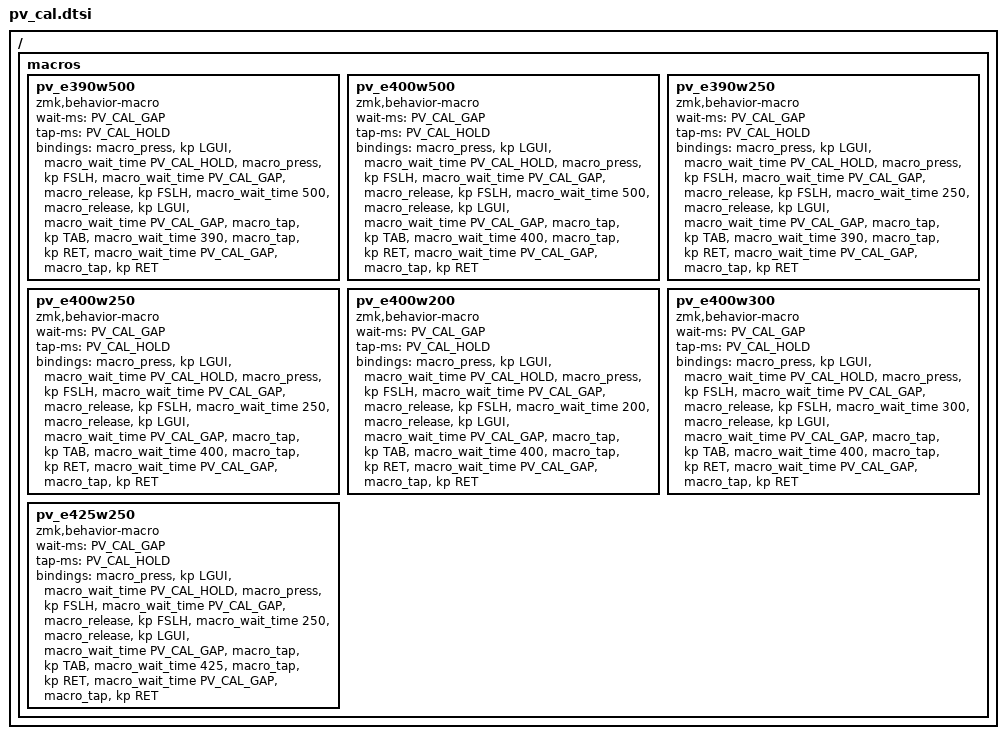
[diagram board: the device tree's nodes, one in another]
/*
 * TEMPORARY Neu paste-values timing calibration — ROUND 4
 *
 * Round 3 CORRECTION: E400@W100 / W150 / E450@W100 were false positives —
 * they did a normal paste + spurious Enter, not paste-as-values.
 * Real hits: E390@W500 ~90%, E400@W250 ~90%. E360 fail, E375 ~30%.
 * Win must be well above 150ms.
 *
 * Combo both lower buttons (pos 6+7) toggles LAYER_PV_CAL. Leave with pos7.
 *
 *               pos0 E390@W500 | pos1 E400@W500
 *               pos2 E390@W250 | pos3 E400@W250
 *               pos4 E400@W200 | pos5 E400@W300
 *               pos6 E425@W250 | pos7 BACK
 *
 * Only count a key as ok if Excel gets *values* (not a normal paste).
 */

#define PV_CAL_HOLD 12
#define PV_CAL_GAP  50

/ {
	macros {
		pv_e390w500: pv_e390w500 {
			compatible = "zmk,behavior-macro";
			#binding-cells = <0>;
			wait-ms = <PV_CAL_GAP>;
			tap-ms = <PV_CAL_HOLD>;
			bindings
				= <&macro_press &kp LGUI>
				, <&macro_wait_time PV_CAL_HOLD>
				, <&macro_press &kp FSLH>
				, <&macro_wait_time PV_CAL_GAP>
				, <&macro_release &kp FSLH>
				, <&macro_wait_time 500>
				, <&macro_release &kp LGUI>
				, <&macro_wait_time PV_CAL_GAP>
				, <&macro_tap &kp TAB>
				, <&macro_wait_time 390>
				, <&macro_tap &kp RET>
				, <&macro_wait_time PV_CAL_GAP>
				, <&macro_tap &kp RET>;
		};
		pv_e400w500: pv_e400w500 {
			compatible = "zmk,behavior-macro";
			#binding-cells = <0>;
			wait-ms = <PV_CAL_GAP>;
			tap-ms = <PV_CAL_HOLD>;
			bindings
				= <&macro_press &kp LGUI>
				, <&macro_wait_time PV_CAL_HOLD>
				, <&macro_press &kp FSLH>
				, <&macro_wait_time PV_CAL_GAP>
				, <&macro_release &kp FSLH>
				, <&macro_wait_time 500>
				, <&macro_release &kp LGUI>
				, <&macro_wait_time PV_CAL_GAP>
				, <&macro_tap &kp TAB>
				, <&macro_wait_time 400>
				, <&macro_tap &kp RET>
				, <&macro_wait_time PV_CAL_GAP>
				, <&macro_tap &kp RET>;
		};
		pv_e390w250: pv_e390w250 {
			compatible = "zmk,behavior-macro";
			#binding-cells = <0>;
			wait-ms = <PV_CAL_GAP>;
			tap-ms = <PV_CAL_HOLD>;
			bindings
				= <&macro_press &kp LGUI>
				, <&macro_wait_time PV_CAL_HOLD>
				, <&macro_press &kp FSLH>
				, <&macro_wait_time PV_CAL_GAP>
				, <&macro_release &kp FSLH>
				, <&macro_wait_time 250>
				, <&macro_release &kp LGUI>
				, <&macro_wait_time PV_CAL_GAP>
				, <&macro_tap &kp TAB>
				, <&macro_wait_time 390>
				, <&macro_tap &kp RET>
				, <&macro_wait_time PV_CAL_GAP>
				, <&macro_tap &kp RET>;
		};
		pv_e400w250: pv_e400w250 {
			compatible = "zmk,behavior-macro";
			#binding-cells = <0>;
			wait-ms = <PV_CAL_GAP>;
			tap-ms = <PV_CAL_HOLD>;
			bindings
				= <&macro_press &kp LGUI>
				, <&macro_wait_time PV_CAL_HOLD>
				, <&macro_press &kp FSLH>
				, <&macro_wait_time PV_CAL_GAP>
				, <&macro_release &kp FSLH>
				, <&macro_wait_time 250>
				, <&macro_release &kp LGUI>
				, <&macro_wait_time PV_CAL_GAP>
				, <&macro_tap &kp TAB>
				, <&macro_wait_time 400>
				, <&macro_tap &kp RET>
				, <&macro_wait_time PV_CAL_GAP>
				, <&macro_tap &kp RET>;
		};
		pv_e400w200: pv_e400w200 {
			compatible = "zmk,behavior-macro";
			#binding-cells = <0>;
			wait-ms = <PV_CAL_GAP>;
			tap-ms = <PV_CAL_HOLD>;
			bindings
				= <&macro_press &kp LGUI>
				, <&macro_wait_time PV_CAL_HOLD>
				, <&macro_press &kp FSLH>
				, <&macro_wait_time PV_CAL_GAP>
				, <&macro_release &kp FSLH>
				, <&macro_wait_time 200>
				, <&macro_release &kp LGUI>
				, <&macro_wait_time PV_CAL_GAP>
				, <&macro_tap &kp TAB>
				, <&macro_wait_time 400>
				, <&macro_tap &kp RET>
				, <&macro_wait_time PV_CAL_GAP>
				, <&macro_tap &kp RET>;
		};
		pv_e400w300: pv_e400w300 {
			compatible = "zmk,behavior-macro";
			#binding-cells = <0>;
			wait-ms = <PV_CAL_GAP>;
			tap-ms = <PV_CAL_HOLD>;
			bindings
				= <&macro_press &kp LGUI>
				, <&macro_wait_time PV_CAL_HOLD>
				, <&macro_press &kp FSLH>
				, <&macro_wait_time PV_CAL_GAP>
				, <&macro_release &kp FSLH>
				, <&macro_wait_time 300>
				, <&macro_release &kp LGUI>
				, <&macro_wait_time PV_CAL_GAP>
				, <&macro_tap &kp TAB>
				, <&macro_wait_time 400>
				, <&macro_tap &kp RET>
				, <&macro_wait_time PV_CAL_GAP>
				, <&macro_tap &kp RET>;
		};
		pv_e425w250: pv_e425w250 {
			compatible = "zmk,behavior-macro";
			#binding-cells = <0>;
			wait-ms = <PV_CAL_GAP>;
			tap-ms = <PV_CAL_HOLD>;
			bindings
				= <&macro_press &kp LGUI>
				, <&macro_wait_time PV_CAL_HOLD>
				, <&macro_press &kp FSLH>
				, <&macro_wait_time PV_CAL_GAP>
				, <&macro_release &kp FSLH>
				, <&macro_wait_time 250>
				, <&macro_release &kp LGUI>
				, <&macro_wait_time PV_CAL_GAP>
				, <&macro_tap &kp TAB>
				, <&macro_wait_time 425>
				, <&macro_tap &kp RET>
				, <&macro_wait_time PV_CAL_GAP>
				, <&macro_tap &kp RET>;
		};
	};
};
